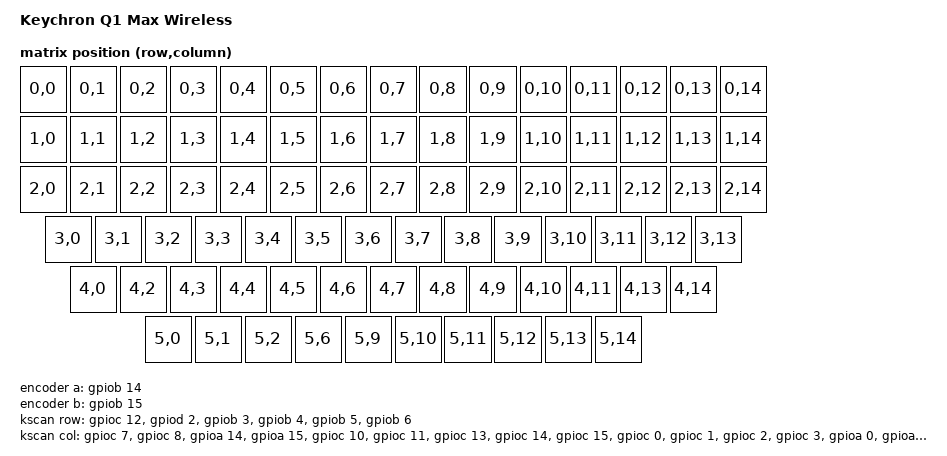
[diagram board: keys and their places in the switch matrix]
// This file was generated from a template. Edit it to match your keyboard.
// See https://docs.zephyrproject.org/4.1.0/hardware/porting/board_porting.html
// and https://zmk.dev/docs/development/hardware-integration/new-shield for more
// instructions.

/dts-v1/;

#include <zephyr/dt-bindings/input/input-event-codes.h>

#include <st/f4/stm32f401Xc.dtsi>
#include <st/f4/stm32f401r(b-c)tx-pinctrl.dtsi>

#include <dt-bindings/zmk/matrix_transform.h>

#include "q1_max_knob-layouts.dtsi"

/ {
    model = "Keychron Q1 Max Wireless";
    compatible = "q1_max_knob";

    chosen {
        zmk,physical-layout = &default_layout;
        zephyr,sram = &sram0;
        zephyr,flash = &flash0;
        zephyr,code-partition = &code_partition;
        zephyr,boot-mode = &retention0;
    };

    encoder: encoder {
        compatible = "alps,ec11";
        a-gpios = <&gpiob 14 (GPIO_ACTIVE_HIGH | GPIO_PULL_UP)>;
        b-gpios = <&gpiob 15 (GPIO_ACTIVE_HIGH | GPIO_PULL_UP)>;
        steps = <80>;
        status = "okay";
    };

    sensors: sensors {
        compatible = "zmk,keymap-sensors";
        sensors = <&encoder>;
        triggers-per-rotation = <5>;
    };

    kscan: kscan {
        // If the hardware does not use a switch matrix, change this to the
        // appropriate driver and update the properties below to match.
        // See https://zmk.dev/docs/config/kscan for supported key scan drivers.
        compatible = "zmk,kscan-gpio-matrix", "gpio-kbd-matrix";
        // Set this to "col2row" or "row2col" to match the hardware. If using
        // "row2col", change the col-gpios to (GPIO_ACTIVE_HIGH | GPIO_PULL_DOWN)
        // and the row-gpios to GPIO_ACTIVE_HIGH.
        diode-direction = "row2col";
        wakeup-source;

        // Replace these comments with the GPIO pins in the matrix.
        // See https://zmk.dev/docs/development/hardware-integration/new-shield#shield-overlays
        col-gpios = <&gpioc 7 (GPIO_ACTIVE_HIGH | GPIO_PULL_DOWN)>,
                    <&gpioc 8 (GPIO_ACTIVE_HIGH | GPIO_PULL_DOWN)>,
                    <&gpioa 14 (GPIO_ACTIVE_HIGH | GPIO_PULL_DOWN)>,
                    <&gpioa 15 (GPIO_ACTIVE_HIGH | GPIO_PULL_DOWN)>,
                    <&gpioc 10 (GPIO_ACTIVE_HIGH | GPIO_PULL_DOWN)>,
                    <&gpioc 11 (GPIO_ACTIVE_HIGH | GPIO_PULL_DOWN)>,
                    <&gpioc 13 (GPIO_ACTIVE_HIGH | GPIO_PULL_DOWN)>,
                    <&gpioc 14 (GPIO_ACTIVE_HIGH | GPIO_PULL_DOWN)>,
                    <&gpioc 15 (GPIO_ACTIVE_HIGH | GPIO_PULL_DOWN)>,
                    <&gpioc 0 (GPIO_ACTIVE_HIGH | GPIO_PULL_DOWN)>,
                    <&gpioc 1 (GPIO_ACTIVE_HIGH | GPIO_PULL_DOWN)>,
                    <&gpioc 2 (GPIO_ACTIVE_HIGH | GPIO_PULL_DOWN)>,
                    <&gpioc 3 (GPIO_ACTIVE_HIGH | GPIO_PULL_DOWN)>,
                    <&gpioa 0 (GPIO_ACTIVE_HIGH | GPIO_PULL_DOWN)>,
                    <&gpioa 1 (GPIO_ACTIVE_HIGH | GPIO_PULL_DOWN)>;

        row-gpios = <&gpioc 12 GPIO_ACTIVE_HIGH>,
                    <&gpiod 2 GPIO_ACTIVE_HIGH>,
                    <&gpiob 3 GPIO_ACTIVE_HIGH>,
                    <&gpiob 4 GPIO_ACTIVE_HIGH>,
                    <&gpiob 5 GPIO_ACTIVE_HIGH>,
                    <&gpiob 6 GPIO_ACTIVE_HIGH>;
    };

    default_transform: default_transform {
        // See https://zmk.dev/docs/development/hardware-integration/new-shield#matrix-transform
        // for how to configure this
        compatible = "zmk,matrix-transform";
        columns = <15>;
        rows = <6>;

        map = <RC(0, 0) RC(0, 1) RC(0, 2) RC(0, 3) RC(0, 4) RC(0, 5) RC(0, 6) RC(0, 7) RC(0, 8) RC(0, 9) RC(0, 10) RC(0, 11) RC(0, 12) RC(0, 13) RC(0, 14)
               RC(1, 0) RC(1, 1) RC(1, 2) RC(1, 3) RC(1, 4) RC(1, 5) RC(1, 6) RC(1, 7) RC(1, 8) RC(1, 9) RC(1, 10) RC(1, 11) RC(1, 12) RC(1, 13) RC(1, 14)
               RC(2, 0) RC(2, 1) RC(2, 2) RC(2, 3) RC(2, 4) RC(2, 5) RC(2, 6) RC(2, 7) RC(2, 8) RC(2, 9) RC(2, 10) RC(2, 11) RC(2, 12) RC(2, 13) RC(2, 14)
               RC(3, 0) RC(3, 1) RC(3, 2) RC(3, 3) RC(3, 4) RC(3, 5) RC(3, 6) RC(3, 7) RC(3, 8) RC(3, 9) RC(3, 10) RC(3, 11) RC(3, 12) RC(3, 13)
               RC(4, 0)          RC(4, 2) RC(4, 3) RC(4, 4) RC(4, 5) RC(4, 6) RC(4, 7) RC(4, 8) RC(4, 9) RC(4, 10) RC(4, 11)           RC(4, 13) RC(4, 14)
               RC(5, 0) RC(5, 1) RC(5, 2)                            RC(5, 6)                   RC(5, 9) RC(5, 10) RC(5, 11) RC(5, 12) RC(5, 13) RC(5, 14)>;
    };

    sram@2000FFFF {
        compatible = "zephyr,memory-region", "mmio-sram";
        reg = <0x2000FFFF 0x1>;
        zephyr,memory-region = "RetainedMem";
        status = "okay";

        retainedmem {
            compatible = "zephyr,retained-ram";
            status = "okay";
            #address-cells = <1>;
            #size-cells = <1>;

            retention0: retention@0 {
                compatible = "zephyr,retention";
                status = "okay";
                reg = <0x0 0x1>;
            };
        };
    };
};

&clk_lsi {
	status = "okay";
};

&clk_hse {
	clock-frequency = <DT_FREQ_M(16)>;
	status = "okay";
};

&pll {
    div-m = <8>;
	mul-n = <96>;
	div-p = <4>;
	div-q = <4>;
	clocks = <&clk_hse>;
    status = "okay";
};

&rcc {
    clocks = <&pll>;
	clock-frequency = <DT_FREQ_M(48)>;
	ahb-prescaler = <1>;
	apb1-prescaler = <2>;
	apb2-prescaler = <1>;
    status = "okay";
};

&spi1 {
    pinctrl-0 = <&spi1_miso_pa6 &spi1_mosi_pa7 &spi1_sck_pa5>;
    pinctrl-names = "default";
    status = "okay";
};

zephyr_udc0: &usbotg_fs {
	pinctrl-0 = <&usb_otg_fs_dm_pa11 &usb_otg_fs_dp_pa12>;
	pinctrl-names = "default";
	status = "okay";
};

&flash0 {
    partitions {
        compatible = "fixed-partitions";
        #address-cells = <1>;
        #size-cells = <1>;

        code_partition: partition@0 {
            compatible = "zephyr,mapped-partition";
            label = "image";
            reg = <0x00000000 DT_SIZE_K(192)>;
        };

        storage_partition: partition@30000 {
            reg = <0x00030000 DT_SIZE_K(64)>;
        };
    };
};

&sram0 {
    /* Shrink SRAM by one byte for DFU support */
    reg = <0x20000000 (DT_SIZE_K(64)-0x1)>;

};
